# R7FA6T2BD register map
Vendor: Renesas Electronics Corporation; Series: RA6; File version: 1.40.00
CPU: CM33 r0p4, little endian, MPU, FPU, VTOR, 4 interrupt priority bits, 96 interrupts
Registers are 32-bit, read-write, reset 0x0 unless marked. A register's access mark holds for its fields unless they carry their own. Offsets are from the block's base; [hi:lo] are bit positions; {n}, {i} and the like mark numbered series.

## SPI_B0 — Serial Peripheral Interface 0
Base 0x4011A000
Same registers: SPI_B1 0x4011A100
0x00 SPDR — SPI Data Register
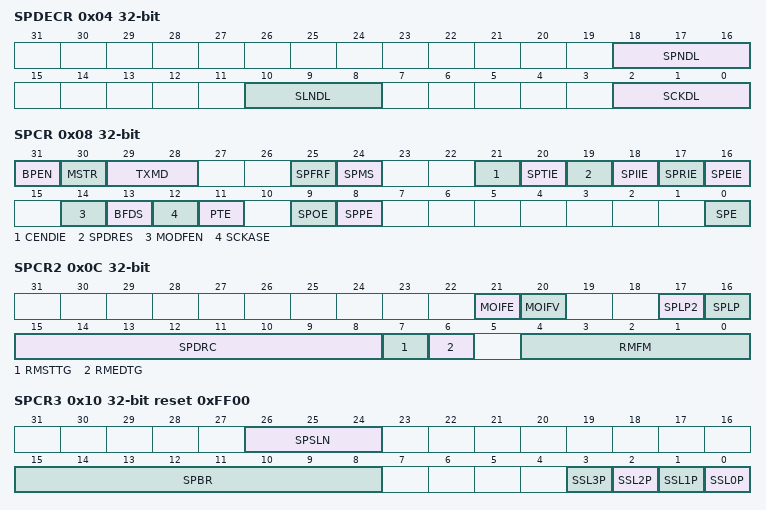
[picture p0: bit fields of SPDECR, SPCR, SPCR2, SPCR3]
0x04 SPDECR — SPI Delay Control Register
  [18:16] SPNDL — SPI Next-Access Delay
    {v}={v+1}RSPCK + 5TCLK (v=0..7)
  [10:8] SLNDL — SSL Negation Delay
    {v}={v+1}RSPCK (v=0..7)
  [2:0] SCKDL — RSPCK Delay
    {v}={v+1}RSPCK (v=0..7)
0x08 SPCR — SPI Control Register
  [31] BPEN — Synchronization Circuit Bypass Enable
    0=Non-Bypass; 1=Bypass
  [30] MSTR — SPI Master/Slave Mode Select
    0=Slave mode; 1=Master mode
  [29:28] TXMD — Communication Mode Select
    0=Transmit-Receive; 1=Transmit only; other=Others (Receive only)
  [25] SPFRF — SPI Frame Format Select
    0=Motorola-SPI; 1=TI-SSP
  [24] SPMS — SPI Mode Select
    0=SPI operation (4-wire); 1=Clock synchronous operation (3-wire)
  [21] CENDIE — SPI Communication End Interrupt Enable
    0=Communication end interrupt request is disabled; 1=Communication end interrupt request is enabled
  [20] SPTIE — SPI Transmit Buffer Empty Interrupt Enable
    0=SPI transmit buffer empty interrupt request is disabled; 1=SPI transmit buffer empty interrupt request is enabled
  [19] SPDRES — SPI receive data ready error select
    0=Receive data full interrupt; 1=Error interrupt
  [18] SPIIE — SPI Idle Interrupt Enable
    0=Idle interrupt request is disabled; 1=Idle interrupt request is enabled
  [17] SPRIE — SPI Receive Buffer Full Interrupt Enable
    0=SPI receive buffer full interrupt request is disabled; 1=SPI receive buffer full interrupt request is enabled
  [16] SPEIE — SPI Error Interrupt Enable
    0=SPI error interrupt request is disabled; 1=SPI error interrupt request is enabled
  [14] MODFEN — Mode Fault Error Detection Enable
    0=Mode fault error detection is disabled; 1=Mode fault error detection is enabled
  [13] BFDS — Between Burst Transfer Frames Delay Select
    0=Delay (RSPCK delay, SSL negation delay and next-access delay) between frames is inserted in burst transfer; 1=Delay between frames is not inserted in burst transfer
  [12] SCKASE — RSPCK Auto-Stop Function Enable
    0=RSPCK auto-stop function is disabled; 1=RSPCK auto-stop function is enabled
  [11] PTE — Parity Self-Diagnosis Enable
    0=Parity circuit self-diagnosis function is disabled; 1=Parity circuit self-diagnosis function is enabled
  [9] SPOE — Parity Mode
    0=Even parity is used for transmission and reception; 1=Odd parity is used for transmission and reception
  [8] SPPE — Parity Enable
    0=A parity bit is not added to transmit data. Received-data parity check is not performed.; 1=A parity bit is added to transmit data. Received-data parity check is performed.
  [0] SPE — SPI Function Enable
    0=SPI function is disabled; 1=SPI function is enabled
0x0C SPCR2 — SPI Control Register 2
  [21] MOIFE — MOSI Idle Fixed Value Enable
    0=The MOSI output value is the last data of previous transfer; 1=The MOSI output value is the set MOIFV bit value
  [20] MOIFV — MOSI Idle Fixed Value
    0=The fixed value of MOSI idle = 0; 1=The fixed value of MOSI idle = 1
  [17] SPLP2 — SPI Loopback 2
    0=Normal mode; 1=Loopback mode (transmit data = receive data)
  [16] SPLP — SPI Loopback
    0=Normal mode; 1=Loopback mode (inverted transmit data = receive data)
  [15:8] SPDRC — SPI received data ready detect adjustment
  [7] RMSTTG wo — Start Trigger in Master Receive only
    1=Receive Start (Writable only when Master Receive only) Reading value is always 0
  [6] RMEDTG wo — End Trigger in Master Receive only
    1=Receive End (Writable only when Master Receive only) Reading value is always 0
  [4:0] RMFM — Frame processing count setting in Master Receive only
0x10 SPCR3 reset 0xFF00 — SPI Control Register 3
  [26:24] SPSLN — SPI Sequence Length
    0=Sequence Length is 1 (Referenced SPCMDn, n = 0→0→…); 1=Sequence Length is 2 (Referenced SPCMDn, n = 0→1→0→…); 2=Sequence Length is 3 (Referenced SPCMDn, n = 0→1→2→0→…); 3=Sequence Length is 4 (Referenced SPCMDn, n = 0→1→2→3→0→…); 4=Sequence Length is 5 (Referenced SPCMDn, n = 0→1→2→3→4→0→…); 5=Sequence Length is 6 (Referenced SPCMDn, n = 0→1→2→3→4→5→0→…); 6=Sequence Length is 7 (Referenced SPCMDn, n = 0→1→2→3→4→5→6→0→…); 7=Sequence Length is 8 (Referenced SPCMDn, n = 0→1→2→3→4→5→6→7→0→…)
  [15:8] SPBR — SPI Bit Rate
  [n] SSL{n}P (n=0..3) — SSL{n} Signal Polarity
    0=The SSL{n} signal is active low (0); 1=The SSL{n} signal is active high (1)
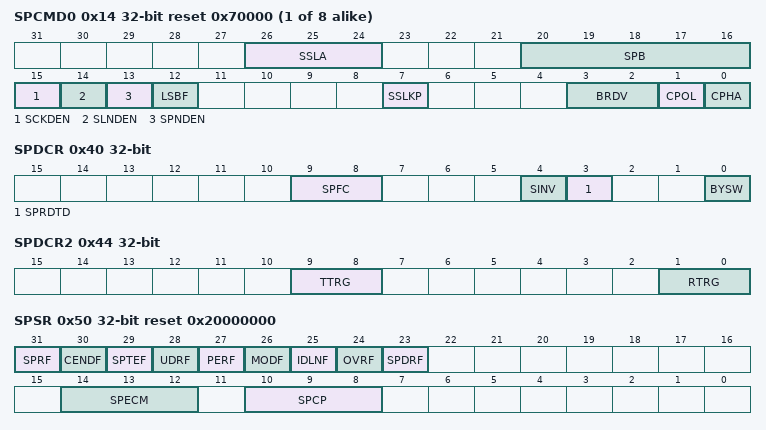
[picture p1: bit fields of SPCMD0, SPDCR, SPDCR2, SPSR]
{0x14+4i} SPCMD{i} (i=0..7) reset 0x70000 — SPI Command Register
  [26:24] SSLA — SSL Signal Assertion
    {v}=SSL{v} (v=0..3); other=Others (Setting prohibited)
  [20:16] SPB — SPI Data Length
  [15] SCKDEN — RSPCK Delay Setting Enable
    0=RSPCK delay is 1 RSPCK; 1=RSPCK delay is the set value of the RSPCK delay register (SPDECR.SCKDL)
  [14] SLNDEN — SSL Negation Delay Setting Enable
    0=[Master] SSL negation delay is 1RSPCK. [Slave in the TI-SSP] SSL negation delay is 1TCLK; 1=SSL negation delay is the set value of the slave select negation delay register (SPDECR.SLNDL)
  [13] SPNDEN — SPI Next-Access Delay Enable
    0=Next-access delay is 1RSPCK + 5TCLK; 1=Next-access delay is the set value of the SPI next-access delay register (SPDECR.SPNDL)
  [12] LSBF — SPI LSB First
    0=MSB first; 1=LSB first
  [7] SSLKP — SSL Signal Level Hold
    0=All SSL signals are negated at the end of transfer; 1=SSL signal level is held after the transfer ends until the next access starts
  [3:2] BRDV — Bit Rate Division
    0=The base bit rate is selected; 1=Two-divided base bit rate is selected; 2=Four-divided base bit rate is selected; 3=Eight-divided base bit rate is selected
  [1] CPOL — RSPCK Polarity
    0=RSPCK in idle state is 0; 1=RSPCK in idle state is 1
  [0] CPHA — RSPCK Phase
    0=Data is sampled at an odd edge and changes at an even edge; 1=Data changes at an odd edge and is sampled at an even edge
0x40 SPDCR — SPI Data Control Register
  [9:8] SPFC — Frame Count
    {v}={v+1} frame (v=0..3)
  [4] SINV — Serial data invert bit
    0=Not invert serial data; 1=Invert serial data
  [3] SPRDTD — SPI Receive Data or Transmit Data Select
    0=The SPDR reads the receive buffer; 1=The SPDR reads the transmit buffer
  [0] BYSW — Byte Swap Operating Mode Select
    0=Byte Swap OFF; 1=Byte Swap ON
0x44 SPDCR2 — SPI Data Control Register 2
  [9:8] TTRG — Transmission FIFO threshold setting
    {v}=threshold {v} (v=0..3)
  [1:0] RTRG — Receive FIFO threshold setting
    {v}=threshold {v} (v=0..3)
0x50 SPSR ro reset 0x20000000 — SPI Status Register
  [31] SPRF — SPI Receive Buffer Full Flag
    0=The number of data stored in the receive FIFO ≤ number of frames set by the SPDCR2.RTRG bit; 1=The number of data stored in the receive FIFO > number of frames set by the SPDCR2.RTRG bit
  [30] CENDF — Communication End Flag
    0=The SPI is not communicating or communicating; 1=The SPI communication completed
  [29] SPTEF — SPI Transmit Buffer Empty Flag
    0=The number of empty stages in the transmit FIFO ≤ the value set in SPDCR2.TTRG; 1=The number of empty stages in the transmit FIFO > the value set in SPDCR2.TTRG
  [28] UDRF — Underrun Error Flag
    0=When MODF=0, neither mode fault error nor underrun error is present. When MODF=1, a mode fault error is present.; 1=When MODF=0, neither mode fault error nor underrun error is present. When MODF=1, an underrun error is present.
  [27] PERF — Parity Error Flag
    0=No parity error is present; 1=A parity error is present
  [26] MODF — Mode Fault Error Flag
    0=Neither mode fault error nor underrun error is present; 1=A mode fault error or underrun error is present
  [25] IDLNF — SPI Idle Flag
    0=The SPI is in the idle state; 1=The SPI is in the transfer state
  [24] OVRF — Overrun Error Flag
    0=No overrun error is present; 1=An overrun error is present
  [23] SPDRF — SPI Receive Data Ready Flag
    0=Receive data ready not detected; 1=Receive data ready detected
  [14:12] SPECM — SPI Error Command
    {v}=SPCMD{v} (v=0..7)
  [10:8] SPCP — SPI Command Pointer
    {v}=SPCMD{v} (v=0..7)
0x58 SPTFSR ro reset 0x4 — SPI Transfer FIFO Status Register
  [2:0] TFDN — Transmit FIFO data empty stage number
0x5C SPRFSR ro reset 0x4 — SPI Receive FIFO Status Register
  [2:0] RFDN — Receive FIFO data store stage number
0x60 SPPSR ro — SPI Polling Register
  [0] SPEPS — SPI Polling Status
    0=SPCR.SPE is 0; 1=SPCR.SPE is 1
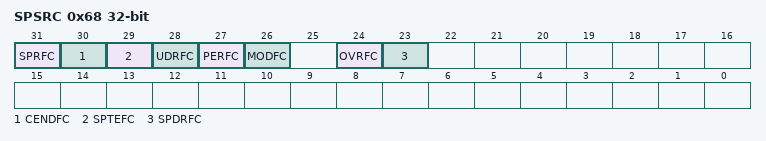
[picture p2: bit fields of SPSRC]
0x68 SPSRC — SPI Status Clear Register
  [31] SPRFC wo — SPI Receive Buffer Full Flag Clear
  [30] CENDFC wo — Communication End Flag Clear
  [29] SPTEFC wo — SPI Transmit Buffer Empty Flag Clear
  [28] UDRFC wo — Underrun Error Flag Clear
  [27] PERFC wo — Parity Error Flag Clear
  [26] MODFC wo — Mode Fault Error Flag Clear
  [24] OVRFC wo — Overrun Error Flag Clear
  [23] SPDRFC wo — SPI Receive Data Ready Flag Clear
0x6C SPFCR — SPI FIFO Clear Register
  [0] SPFRST wo — SPI FIFO clear
